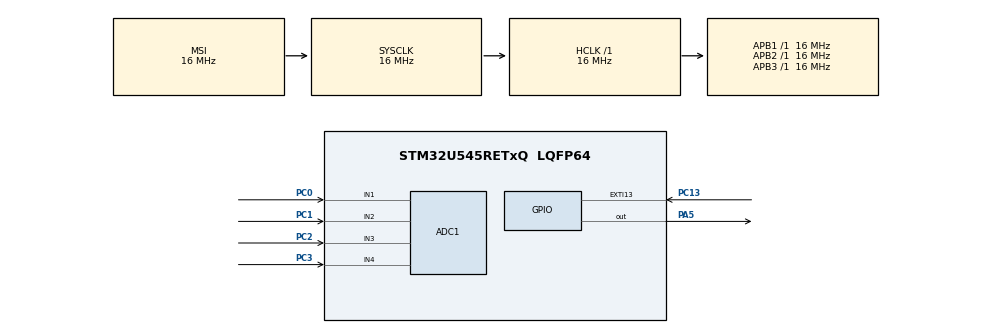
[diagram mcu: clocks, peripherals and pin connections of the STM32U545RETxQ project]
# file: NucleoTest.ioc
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ADC1.Channel-0\#ChannelRegularConversion=ADC_CHANNEL_1
ADC1.Channel-1\#ChannelRegularConversion=ADC_CHANNEL_2
ADC1.Channel-2\#ChannelRegularConversion=ADC_CHANNEL_3
ADC1.Channel-3\#ChannelRegularConversion=ADC_CHANNEL_4
ADC1.MonitoredBy-0\#ChannelRegularConversion=__NULL
ADC1.MonitoredBy-1\#ChannelRegularConversion=__NULL
ADC1.MonitoredBy-2\#ChannelRegularConversion=__NULL
ADC1.MonitoredBy-3\#ChannelRegularConversion=__NULL
ADC1.NbrOfConversion=4
ADC1.NbrOfConversionFlag=1
ADC1.OffsetNumber-0\#ChannelRegularConversion=ADC_OFFSET_NONE
ADC1.OffsetNumber-1\#ChannelRegularConversion=ADC_OFFSET_NONE
ADC1.OffsetNumber-2\#ChannelRegularConversion=ADC_OFFSET_NONE
ADC1.OffsetNumber-3\#ChannelRegularConversion=ADC_OFFSET_NONE
ADC1.OversamplingMode=ENABLE
ADC1.Rank-0\#ChannelRegularConversion=1
ADC1.Rank-1\#ChannelRegularConversion=2
ADC1.Rank-2\#ChannelRegularConversion=3
ADC1.Rank-3\#ChannelRegularConversion=4
ADC1.Ratio1=16
ADC1.SamplingTime-0\#ChannelRegularConversion=ADC_SAMPLETIME_5CYCLE
ADC1.SamplingTime-1\#ChannelRegularConversion=ADC_SAMPLETIME_5CYCLE
ADC1.SamplingTime-2\#ChannelRegularConversion=ADC_SAMPLETIME_5CYCLE
ADC1.SamplingTime-3\#ChannelRegularConversion=ADC_SAMPLETIME_5CYCLE
ADC1.master=1
CORTEX_M33_NS.userName=CORTEX_M33
GPDMA1.DESTBURSTLENGTH_GPDMACH0=1
GPDMA1.DESTDATAWIDTH_GPDMACH0=DMA_DEST_DATAWIDTH_WORD
GPDMA1.DESTINC_GPDMACH0=DMA_DINC_INCREMENTED
GPDMA1.IPHANDLE_GPDMACH0-SIMPLEREQUEST_GPDMACH0=__NULL
GPDMA1.REQUEST_GPDMACH0=GPDMA1_REQUEST_ADC1
GPDMA1.SRCBURSTLENGTH_GPDMACH0=1
GPDMA1.SRCDATAWIDTH_GPDMACH0=DMA_SRC_DATAWIDTH_HALFWORD
GPDMA1.SRCINC_GPDMACH0=DMA_SINC_FIXED
Mcu.Family=STM32U5
Mcu.Name=STM32U545RETxQ
Mcu.Package=LQFP64
NUCLEO-U545RE-Q.BUTTON=1
NUCLEO-U545RE-Q.LD2=true
NUCLEO-U545RE-Q.VCP=true
NVIC.ADC1_IRQn=true\:0\:0\:false\:false\:true\:true\:true\:true
NVIC.EXTI13_IRQn=true\:0\:0\:false\:false\:true\:false\:true\:true
NVIC.GPDMA1_Channel0_IRQn=true\:0\:0\:false\:false\:true\:false\:true\:true
NVIC.PriorityGroup=NVIC_PRIORITYGROUP_4
PA13\ (JTMS/SWDIO).Mode=Serial_Wire
PA13\ (JTMS/SWDIO).Signal=DEBUG_JTMS-SWDIO
PA14\ (JTCK/SWCLK).Mode=Serial_Wire
PA14\ (JTCK/SWCLK).Signal=DEBUG_JTCK-SWCLK
PA5.Signal=GPIO_Output
PC0.Mode=IN1-Single-Ended
PC0.Signal=ADC1_IN1
PC1.Mode=IN2-Single-Ended
PC1.Signal=ADC1_IN2
PC13.Signal=GPXTI13
PC2.Mode=IN3-Single-Ended
PC2.Signal=ADC1_IN3
PC3.Mode=IN4-Single-Ended
PC3.Signal=ADC1_IN4
PWR.PowerMode=PWR_SMPS_SUPPLY
ProjectManager.HeapSize=0x200
ProjectManager.StackSize=0x400
ProjectManager.TargetToolchain=EWARM V8.50
RCC.ADCCLockSelection=RCC_ADCDACCLKSOURCE_MSIK
RCC.ADCFreq_Value=16000000
RCC.AHBFreq_Value=16000000
RCC.APB1Freq_Value=16000000
RCC.APB1TimFreq_Value=16000000
RCC.APB2Freq_Value=16000000
RCC.APB2TimFreq_Value=16000000
RCC.APB3Freq_Value=16000000
RCC.CortexFreq_Value=16000000
RCC.DACCLockSelectionVirtual=RCC_DAC1CLKSOURCE_LSI
RCC.DACCLockSelectionVirtualString=RCC_DAC1CLKSOURCE_LSI
RCC.EPOD_VALUE=16000000
RCC.HCLKFreq_Value=16000000
RCC.HSE_VALUE=16000000
RCC.HSI48_VALUE=48000000
RCC.HSI_VALUE=16000000
RCC.LSE_VALUE=32768
RCC.LSIDIV_VALUE=32000
RCC.MSIClockRange=RCC_MSIRANGE_2
RCC.MSIKClockRange=RCC_MSIKRANGE_2
RCC.MSI_VALUE=16000000
RCC.SYSCLKFreq_VALUE=16000000
RCC.USBFreq_Value=48000000
RCC.VCOOutputFreq_Value=2064000000
VP_GPDMA1_VS_GPDMACH0.Mode=SIMPLEREQUEST_GPDMACH0
VP_ICACHE_VS_ICACHE.Mode=DirectMappedCache
VP_LPBAMQUEUE_VS_QUEUE.Mode=QUEUEMODE
VP_MEMORYMAP_VS_MEMORYMAP.Mode=CurAppReg
VP_NUCLEO-U545RE-Q_VS_BSP_COMMON.Mode=COMMON
VP_PWR_VS_LPOM.Mode=PowerOptimisation
VP_PWR_VS_SECSignals.Mode=Security/Privilege
VP_PWR_Vdda.Mode=isolationVdda
board=NUCLEO-U545RE-Q

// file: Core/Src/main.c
/* USER CODE BEGIN Header */
/**
  ******************************************************************************
  * @file           : main.c
  * @brief          : Main program body
  ******************************************************************************
  * @attention
  *
  * Copyright (c) 2024 STMicroelectronics.
  * All rights reserved.
  *
  * This software is licensed under terms that can be found in the LICENSE file
  * in the root directory of this software component.
  * If no LICENSE file comes with this software, it is provided AS-IS.
  *
  ******************************************************************************
  */
/* USER CODE END Header */
#include "main.h"
#include "adc.h"
#include "gpdma.h"
#include "icache.h"
#include "memorymap.h"
#include "gpio.h"

COM_InitTypeDef BspCOMInit;

/* USER CODE BEGIN PV */
#define ADC_DATA_SIZE 4
uint32_t adc_data[ADC_DATA_SIZE];
  static uint8_t adc_complete = 0;
/* USER CODE END PV */

void SystemClock_Config(void);
static void SystemPower_Config(void);

int main(void)
{

  /* MCU Configuration--------------------------------------------------------*/

  /* Reset of all peripherals, Initializes the Flash interface and the Systick. */
  HAL_Init();

  /* Configure the system clock */
  SystemClock_Config();

  /* Configure the System Power */
  SystemPower_Config();

  /* Initialize all configured peripherals */
  MX_GPIO_Init();
  MX_GPDMA1_Init();
  MX_ADC1_Init();
  MX_ICACHE_Init();

  /* Initialize led */
  BSP_LED_Init(LED_GREEN);

  /* Initialize USER push-button, will be used to trigger an interrupt each time it's pressed.*/
  BSP_PB_Init(BUTTON_USER, BUTTON_MODE_EXTI);

  /* Initialize COM1 port (115200, 8 bits (7-bit data + 1 stop bit), no parity */
  BspCOMInit.BaudRate   = 115200;
  BspCOMInit.WordLength = COM_WORDLENGTH_8B;
  BspCOMInit.StopBits   = COM_STOPBITS_1;
  BspCOMInit.Parity     = COM_PARITY_NONE;
  BspCOMInit.HwFlowCtl  = COM_HWCONTROL_NONE;
  if (BSP_COM_Init(COM1, &BspCOMInit) != BSP_ERROR_NONE)
  {
    Error_Handler();
  }

  /* Infinite loop */
  /* USER CODE BEGIN WHILE */

  HAL_ADCEx_Calibration_Start(&hadc1, ADC_CALIB_OFFSET_LINEARITY, ADC_SINGLE_ENDED);
  HAL_ADCEx_Calibration_Start(&hadc1, ADC_CALIB_OFFSET, ADC_SINGLE_ENDED);

  if(HAL_ADC_Start_DMA(&hadc1, adc_data, ADC_DATA_SIZE) != HAL_OK)
  {
    while(1) {
      BSP_LED_Toggle(LED_GREEN);
      HAL_Delay(250);
    }
  }

  while (1)
  {
    if(adc_complete != 0){
      adc_complete = 0;

      if(HAL_ADC_Start_DMA(&hadc1, adc_data, ADC_DATA_SIZE) != HAL_OK) // Runs once every 15MS at the start of a task.
      {
        while(1) {
          BSP_LED_Toggle(LED_GREEN);
          HAL_Delay(250);
        }
      }
    /* USER CODE END WHILE */

    /* USER CODE BEGIN 3 */

    }
   HAL_Delay(500);
  /* USER CODE END 3 */
  }
}

void HAL_ADC_ConvCpltCallback(ADC_HandleTypeDef *hadc) //This never returns after the first call.
{
  adc_complete = 1; //This is usually a semaphore incrementing for new data ready.
  BSP_LED_Toggle(LED_GREEN);
}

void SystemClock_Config(void)
{
  RCC_OscInitTypeDef RCC_OscInitStruct = {0};
  RCC_ClkInitTypeDef RCC_ClkInitStruct = {0};

  /** Configure the main internal regulator output voltage
  */
  if (HAL_PWREx_ControlVoltageScaling(PWR_REGULATOR_VOLTAGE_SCALE4) != HAL_OK)
  {
    Error_Handler();
  }

  /** Initializes the CPU, AHB and APB buses clocks
  */
  RCC_OscInitStruct.OscillatorType = RCC_OSCILLATORTYPE_MSI|RCC_OSCILLATORTYPE_MSIK;
  RCC_OscInitStruct.MSIState = RCC_MSI_ON;
  RCC_OscInitStruct.MSICalibrationValue = RCC_MSICALIBRATION_DEFAULT;
  RCC_OscInitStruct.MSIClockRange = RCC_MSIRANGE_2;
  RCC_OscInitStruct.MSIKClockRange = RCC_MSIKRANGE_2;
  RCC_OscInitStruct.MSIKState = RCC_MSIK_ON;
  RCC_OscInitStruct.PLL.PLLState = RCC_PLL_NONE;
  if (HAL_RCC_OscConfig(&RCC_OscInitStruct) != HAL_OK)
  {
    Error_Handler();
  }

  /** Initializes the CPU, AHB and APB buses clocks
  */
  RCC_ClkInitStruct.ClockType = RCC_CLOCKTYPE_HCLK|RCC_CLOCKTYPE_SYSCLK
                              |RCC_CLOCKTYPE_PCLK1|RCC_CLOCKTYPE_PCLK2
                              |RCC_CLOCKTYPE_PCLK3;
  RCC_ClkInitStruct.SYSCLKSource = RCC_SYSCLKSOURCE_MSI;
  RCC_ClkInitStruct.AHBCLKDivider = RCC_SYSCLK_DIV1;
  RCC_ClkInitStruct.APB1CLKDivider = RCC_HCLK_DIV1;
  RCC_ClkInitStruct.APB2CLKDivider = RCC_HCLK_DIV1;
  RCC_ClkInitStruct.APB3CLKDivider = RCC_HCLK_DIV1;

  if (HAL_RCC_ClockConfig(&RCC_ClkInitStruct, FLASH_LATENCY_1) != HAL_OK)
  {
    Error_Handler();
  }
}

/**
  * @brief Power Configuration
  * @retval None
  */
static void SystemPower_Config(void)
{

  /*
   * Switch to SMPS regulator instead of LDO
   */
  if (HAL_PWREx_ConfigSupply(PWR_SMPS_SUPPLY) != HAL_OK)
  {
    Error_Handler();
  }
}

void Error_Handler(void)
{
  __disable_irq();
  while (1)
  {
  }
}
